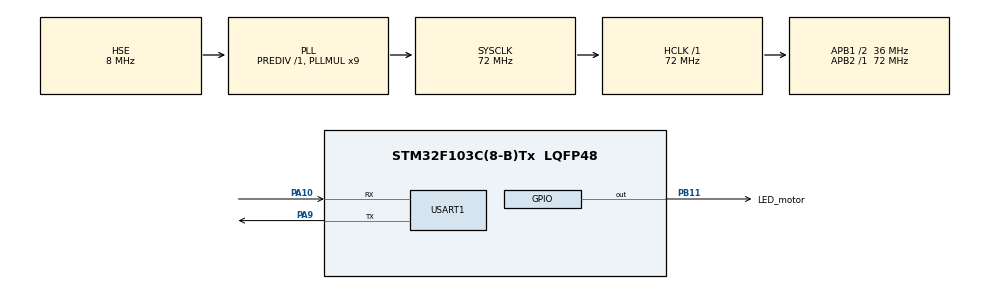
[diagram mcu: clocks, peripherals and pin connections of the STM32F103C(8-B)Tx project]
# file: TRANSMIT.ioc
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Mcu.Family=STM32F1
Mcu.Name=STM32F103C(8-B)Tx
Mcu.Package=LQFP48
NVIC.PriorityGroup=NVIC_PRIORITYGROUP_4
NVIC.USART1_IRQn=true\:0\:0\:false\:false\:true\:true
PA10.Mode=Asynchronous
PA10.Signal=USART1_RX
PA13.Mode=Serial_Wire
PA13.Signal=SYS_JTMS-SWDIO
PA14.Mode=Serial_Wire
PA14.Signal=SYS_JTCK-SWCLK
PA9.Mode=Asynchronous
PA9.Signal=USART1_TX
PB11.GPIO_Label=LED_motor
PB11.Signal=GPIO_Output
PD0-OSC_IN.Mode=HSE-External-Oscillator
PD0-OSC_IN.Signal=RCC_OSC_IN
PD1-OSC_OUT.Mode=HSE-External-Oscillator
PD1-OSC_OUT.Signal=RCC_OSC_OUT
ProjectManager.HeapSize=0x200
ProjectManager.StackSize=0x400
ProjectManager.TargetToolchain=MDK-ARM V5
RCC.AHBFreq_Value=72000000
RCC.APB1CLKDivider=RCC_HCLK_DIV2
RCC.APB1Freq_Value=36000000
RCC.APB1TimFreq_Value=72000000
RCC.APB2Freq_Value=72000000
RCC.APB2TimFreq_Value=72000000
RCC.HCLKFreq_Value=72000000
RCC.PLLMUL=RCC_PLL_MUL9
RCC.PLLSourceVirtual=RCC_PLLSOURCE_HSE
RCC.SYSCLKFreq_VALUE=72000000
RCC.SYSCLKSource=RCC_SYSCLKSOURCE_PLLCLK
RCC.USBFreq_Value=72000000
USART1.VirtualMode=VM_ASYNC
board=custom

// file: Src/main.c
/**
  ******************************************************************************
  * @file           : main.c
  * @brief          : Main program body
  ******************************************************************************
  ** This notice applies to any and all portions of this file
  * that are not between comment pairs USER CODE BEGIN and
  * USER CODE END. Other portions of this file, whether
  * inserted by the user or by software development tools
  * are owned by their respective copyright owners.
  *
  * COPYRIGHT(c) 2019 STMicroelectronics
  *
  * Redistribution and use in source and binary forms, with or without modification,
  * are permitted provided that the following conditions are met:
  *   1. Redistributions of source code must retain the above copyright notice,
  *      this list of conditions and the following disclaimer.
  *   2. Redistributions in binary form must reproduce the above copyright notice,
  *      this list of conditions and the following disclaimer in the documentation
  *      and/or other materials provided with the distribution.
  *   3. Neither the name of STMicroelectronics nor the names of its contributors
  *      may be used to endorse or promote products derived from this software
  *      without specific prior written permission.
  *
  * THIS SOFTWARE IS PROVIDED BY THE COPYRIGHT HOLDERS AND CONTRIBUTORS "AS IS"
  * AND ANY EXPRESS OR IMPLIED WARRANTIES, INCLUDING, BUT NOT LIMITED TO, THE
  * IMPLIED WARRANTIES OF MERCHANTABILITY AND FITNESS FOR A PARTICULAR PURPOSE ARE
  * DISCLAIMED. IN NO EVENT SHALL THE COPYRIGHT HOLDER OR CONTRIBUTORS BE LIABLE
  * FOR ANY DIRECT, INDIRECT, INCIDENTAL, SPECIAL, EXEMPLARY, OR CONSEQUENTIAL
  * DAMAGES (INCLUDING, BUT NOT LIMITED TO, PROCUREMENT OF SUBSTITUTE GOODS OR
  * SERVICES; LOSS OF USE, DATA, OR PROFITS; OR BUSINESS INTERRUPTION) HOWEVER
  * CAUSED AND ON ANY THEORY OF LIABILITY, WHETHER IN CONTRACT, STRICT LIABILITY,
  * OR TORT (INCLUDING NEGLIGENCE OR OTHERWISE) ARISING IN ANY WAY OUT OF THE USE
  * OF THIS SOFTWARE, EVEN IF ADVISED OF THE POSSIBILITY OF SUCH DAMAGE.
  *
  ******************************************************************************
  */
#include "main.h"
#include "stm32f1xx_hal.h"

/* USER CODE BEGIN Includes */
#include "CTR_nrf24l01.h"
#include "stdio.h"
#include "string.h"
/* USER CODE END Includes */

UART_HandleTypeDef huart1;

/* USER CODE BEGIN PV */
/* Private variables ---------------------------------------------------------*/
void NRF24L01_Config()
{
	CTR_nrfPinConfig();
}

/* USER CODE END PV */

void SystemClock_Config(void);
static void MX_GPIO_Init(void);
static void MX_USART1_UART_Init(void);

/* USER CODE BEGIN PFP */
/* Private function prototypes -----------------------------------------------*/

/* USER CODE END PFP */

/* USER CODE BEGIN 0 */
//uint8_t CTR_SENDBUFF[32];
uint8_t chuoi[32];

char ok[32]="ok\r\n";
char check_1b_bat[32]="bat bom 1b\r\n";
char check_1b_tat[32]="tat bom 1b\r\n";
char check_2b_bat[32]="bat bom 2b\r\n";
char check_2b_tat[32]="tat bom 2b\r\n";

uint8_t test[32]="start\r\n";
/* USER CODE END 0 */

int main(void)
{

  /* MCU Configuration----------------------------------------------------------*/

  /* Reset of all peripherals, Initializes the Flash interface and the Systick. */
  HAL_Init();

  /* Configure the system clock */
  SystemClock_Config();

  /* Initialize all configured peripherals */
  MX_GPIO_Init();
  MX_USART1_UART_Init();
  /* USER CODE BEGIN 2 */
	NRF24L01_Config();
	CTR_nrfInit(); // khoi tao
	CTR_nrfSetRX();
	// them doan ma can gui vao buffer gui

  /* USER CODE END 2 */

  /* Infinite loop */
	while (1)
	{

  /* USER CODE BEGIN 3 */
		//thoi_gian_truyen=0;
		if(CTR_nrfGetPacket(chuoi)==1)
		{
			int chuoi_check_bat = strcmp(chuoi, check_2b_bat);
			int chuoi_check_tat = strcmp(chuoi, check_2b_tat);
			if(chuoi_check_bat == 0)
			{
				HAL_GPIO_WritePin(LED_motor_GPIO_Port, LED_motor_Pin, GPIO_PIN_SET);
				HAL_UART_Transmit(&huart1,chuoi,32,5);//xem chuoi nhan duoc tren pc
				memset(chuoi,0x00,32);//xoa chuoi
			}
			else if(chuoi_check_tat == 0)
			{
				HAL_GPIO_WritePin(LED_motor_GPIO_Port, LED_motor_Pin, GPIO_PIN_RESET);
				HAL_UART_Transmit(&huart1,chuoi,32,5);//xem chuoi nhan duoc tren pc
				memset(chuoi,0x00,32);//xoa chuoi
			}
		}
		CTR_nrfSetRX();
	}
  /* USER CODE END 3 */

}

void SystemClock_Config(void)
{

  RCC_OscInitTypeDef RCC_OscInitStruct;
  RCC_ClkInitTypeDef RCC_ClkInitStruct;

    /**Initializes the CPU, AHB and APB busses clocks
    */
  RCC_OscInitStruct.OscillatorType = RCC_OSCILLATORTYPE_HSE;
  RCC_OscInitStruct.HSEState = RCC_HSE_ON;
  RCC_OscInitStruct.HSEPredivValue = RCC_HSE_PREDIV_DIV1;
  RCC_OscInitStruct.HSIState = RCC_HSI_ON;
  RCC_OscInitStruct.PLL.PLLState = RCC_PLL_ON;
  RCC_OscInitStruct.PLL.PLLSource = RCC_PLLSOURCE_HSE;
  RCC_OscInitStruct.PLL.PLLMUL = RCC_PLL_MUL9;
  if (HAL_RCC_OscConfig(&RCC_OscInitStruct) != HAL_OK)
  {
    _Error_Handler(__FILE__, __LINE__);
  }

    /**Initializes the CPU, AHB and APB busses clocks
    */
  RCC_ClkInitStruct.ClockType = RCC_CLOCKTYPE_HCLK|RCC_CLOCKTYPE_SYSCLK
                              |RCC_CLOCKTYPE_PCLK1|RCC_CLOCKTYPE_PCLK2;
  RCC_ClkInitStruct.SYSCLKSource = RCC_SYSCLKSOURCE_PLLCLK;
  RCC_ClkInitStruct.AHBCLKDivider = RCC_SYSCLK_DIV1;
  RCC_ClkInitStruct.APB1CLKDivider = RCC_HCLK_DIV2;
  RCC_ClkInitStruct.APB2CLKDivider = RCC_HCLK_DIV1;

  if (HAL_RCC_ClockConfig(&RCC_ClkInitStruct, FLASH_LATENCY_2) != HAL_OK)
  {
    _Error_Handler(__FILE__, __LINE__);
  }

    /**Configure the Systick interrupt time
    */
  HAL_SYSTICK_Config(HAL_RCC_GetHCLKFreq()/1000);

    /**Configure the Systick
    */
  HAL_SYSTICK_CLKSourceConfig(SYSTICK_CLKSOURCE_HCLK);

  /* SysTick_IRQn interrupt configuration */
  HAL_NVIC_SetPriority(SysTick_IRQn, 0, 0);
}

/* USART1 init function */
static void MX_USART1_UART_Init(void)
{

  huart1.Instance = USART1;
  huart1.Init.BaudRate = 115200;
  huart1.Init.WordLength = UART_WORDLENGTH_8B;
  huart1.Init.StopBits = UART_STOPBITS_1;
  huart1.Init.Parity = UART_PARITY_NONE;
  huart1.Init.Mode = UART_MODE_TX_RX;
  huart1.Init.HwFlowCtl = UART_HWCONTROL_NONE;
  huart1.Init.OverSampling = UART_OVERSAMPLING_16;
  if (HAL_UART_Init(&huart1) != HAL_OK)
  {
    _Error_Handler(__FILE__, __LINE__);
  }

}

/** Configure pins as
        * Analog
        * Input
        * Output
        * EVENT_OUT
        * EXTI
*/
static void MX_GPIO_Init(void)
{

  GPIO_InitTypeDef GPIO_InitStruct;

  /* GPIO Ports Clock Enable */
  __HAL_RCC_GPIOD_CLK_ENABLE();
  __HAL_RCC_GPIOB_CLK_ENABLE();
  __HAL_RCC_GPIOA_CLK_ENABLE();

  /*Configure GPIO pin Output Level */
  HAL_GPIO_WritePin(LED_motor_GPIO_Port, LED_motor_Pin, GPIO_PIN_RESET);

  /*Configure GPIO pin : LED_motor_Pin */
  GPIO_InitStruct.Pin = LED_motor_Pin;
  GPIO_InitStruct.Mode = GPIO_MODE_OUTPUT_PP;
  GPIO_InitStruct.Pull = GPIO_NOPULL;
  GPIO_InitStruct.Speed = GPIO_SPEED_FREQ_LOW;
  HAL_GPIO_Init(LED_motor_GPIO_Port, &GPIO_InitStruct);

}

void _Error_Handler(char *file, int line)
{
	while(1)
	{
	}
}

/************************ (C) COPYRIGHT STMicroelectronics *****END OF FILE****/
